VERSION "snapshot-all-cases"

NS_ :

BS_:

BU_: NODE_A NODE_B NODE_C DBG

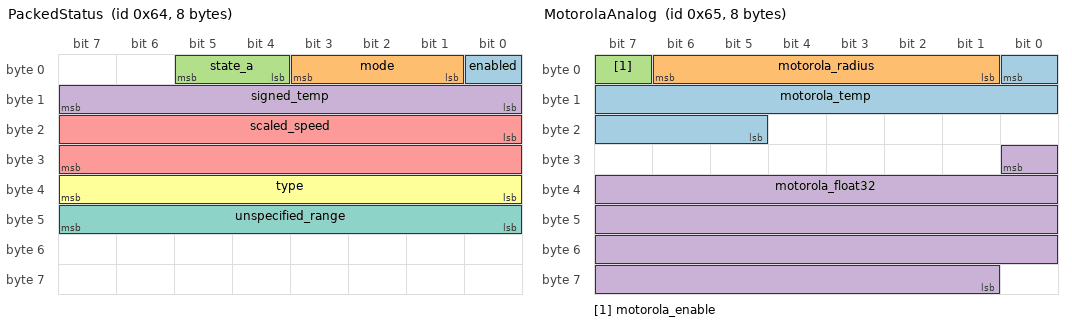
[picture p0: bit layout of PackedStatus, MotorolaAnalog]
BO_ 100 PackedStatus: 8 NODE_A
 SG_ enabled : 0|1@1+ (1,0) [0|1] "" NODE_B
 SG_ mode : 1|3@1+ (1,0) [0|7] "" NODE_B
 SG_ state_a : 4|2@1+ (1,0) [0|3] "" NODE_B
 SG_ signed_temp : 8|8@1- (1,-40) [-168|87] "degC" NODE_B
 SG_ scaled_speed : 16|16@1+ (0.01,0) [0|655.35] "kph" NODE_B
 SG_ type : 32|8@1+ (1,0) [0|255] "" NODE_B
 SG_ unspecified_range : 40|8@1+ (1,0) [0|0] "" NODE_B

BO_ 101 MotorolaAnalog: 8 NODE_A
 SG_ motorola_temp : 0|12@0- (0.01,250) [229.52|270.47] "degK" NODE_B,NODE_C
 SG_ motorola_radius : 6|6@0+ (0.1,0) [0|5] "m" NODE_B
 SG_ motorola_enable : 7|1@0+ (1,0) [0|1] "-" NODE_B
 SG_ motorola_float32 : 24|32@0- (0.1,0) [0|5] "m" NODE_C

BO_ 102 FloatPayload32: 8 NODE_A
 SG_ float32_a : 0|32@1- (1,0) [-1000|1000] "" DBG
 SG_ float32_b : 32|32@1- (1,0) [-1000|1000] "" DBG

BO_ 103 FloatPayload64: 8 NODE_A
 SG_ float64_value : 0|64@1- (1,0) [-1000|1000] "" DBG

BO_ 104 MuxedTelemetry: 8 NODE_A
 SG_ mux M : 0|4@1+ (1,0) [0|15] "" NODE_B
 SG_ common_count : 4|12@1+ (1,0) [0|4095] "" NODE_B
 SG_ mux0_distance m0 : 16|16@1+ (0.1,0) [0|6553.5] "m" NODE_B
 SG_ mux0_state m0 : 32|8@1+ (1,0) [0|255] "" NODE_B
 SG_ mux1_signed m1 : 16|16@1- (1,0) [-32768|32767] "" NODE_B
 SG_ mux1_choice m1 : 32|8@1+ (1,0) [0|255] "" NODE_B

BO_ 105 EmptyZeroDlc: 0 NODE_A

BO_ 2147483652 ExtendedClassic: 8 NODE_B
 SG_ ext_counter : 0|8@1+ (1,0) [0|255] "" NODE_A

BO_ 2147483653 ExtendedCanFd: 64 NODE_B
 SG_ fd_word0 : 0|64@1+ (1,0) [0|4294967296] "" NODE_A
 SG_ fd_word1 : 64|64@1+ (1,0) [0|4294967296] "" NODE_A

BO_ 120 VariableLength: 10 NODE_C
 SG_ var_a : 0|15@1+ (1,0) [0|32767] "" NODE_A
 SG_ var_b : 15|15@1+ (1,0) [0|32767] "" NODE_A
 SG_ var_c : 30|15@1+ (1,0) [0|32767] "" NODE_A
 SG_ var_d : 45|15@1+ (1,0) [0|32767] "" NODE_A
 SG_ var_e : 60|15@1+ (1,0) [0|32767] "" NODE_A

BO_ 2503213569 J1939Snapshot: 8 NODE_A
 SG_ j1939_signal : 0|8@1- (1,0) [-128|127] "" NODE_B

BO_TX_BU_ 102 : NODE_A,NODE_B,NODE_C;

CM_ BU_ NODE_A "Primary snapshot node";
CM_ BO_ 100 "Packed little-endian status values";
CM_ SG_ 100 scaled_speed "Scaled speed signal used by snapshot testing";
CM_ BO_ 101 "Motorola signal layout with comments";
CM_ SG_ 101 motorola_temp "Signed big-endian scaled temperature";

BA_DEF_ "DBName" STRING ;
BA_DEF_ "BusType" STRING ;
BA_DEF_ "ProtocolType" STRING ;
BA_DEF_ BO_ "VFrameFormat" ENUM  "StandardCAN","ExtendedCAN","reserved","J1939PG","reserved","reserved","reserved","reserved","reserved","reserved","reserved","reserved","reserved","reserved","StandardCAN_FD","ExtendedCAN_FD";
BA_DEF_ BO_ "GenMsgCycleTime" INT 0 10000;
BA_DEF_ SG_ "GenSigStartValue" INT -2147483648 2147483647;
BA_DEF_ SG_ "SPN" INT 0 524287;
BA_DEF_REL_ BU_SG_REL_ "SigTimeoutTime" INT 0 65535;
BA_DEF_DEF_ "DBName" "";
BA_DEF_DEF_ "BusType" "CAN";
BA_DEF_DEF_ "ProtocolType" "";
BA_DEF_DEF_ "VFrameFormat" "StandardCAN";
BA_DEF_DEF_ "GenMsgCycleTime" 0;
BA_DEF_DEF_ "GenSigStartValue" 0;
BA_DEF_DEF_ "SPN" 0;
BA_DEF_DEF_REL_ "SigTimeoutTime" 0;
BA_ "DBName" "snapshot_cases";
BA_ "BusType" "CAN FD";
BA_ "ProtocolType" "J1939";
BA_ "GenMsgCycleTime" BO_ 100 100;
BA_ "GenMsgCycleTime" BO_ 104 20;
BA_ "VFrameFormat" BO_ 2147483652 1;
BA_ "VFrameFormat" BO_ 2147483653 15;
BA_ "VFrameFormat" BO_ 2503213569 3;
BA_ "GenSigStartValue" SG_ 100 scaled_speed 10;
BA_ "SPN" SG_ 2503213569 j1939_signal 500;
BA_REL_ "SigTimeoutTime" BU_SG_REL_ NODE_B SG_ 100 scaled_speed 6000;

VAL_ 100 mode 3 "ModeSleep" 2 "ModeRun" 1 "ModeInit" 0 "ModeOff" ;
VAL_ 100 state_a 1 "On" 0 "Off" ;
VAL_ 101 motorola_enable 1 "Enabled" 0 "Disabled" ;
VAL_ 104 mux1_choice 2 "Two" 1 "One" 0 "Zero" ;

SIG_GROUP_ 104 Mux0Group 1 : mux0_distance mux0_state;
SIG_VALTYPE_ 101 motorola_float32 : 1;
SIG_VALTYPE_ 102 float32_a : 1;
SIG_VALTYPE_ 102 float32_b : 1;
SIG_VALTYPE_ 103 float64_value : 2;
